# UPD70F3508 register map
Vendor: Renesas; Series: V850E2/Px4; File version: 1.0
CPU: other r0p0, little endian, no MPU, FPU, 4 interrupt priority bits
Registers are 8-bit, read-write, reset 0x0 unless marked. A register's access mark holds for its fields unless they carry their own. Offsets are from the block's base; [hi:lo] are bit positions.

## TAPA0 — Timer Option Module 0 Status and Trigger Registers (base1 region)
Base 0xFFFFD400
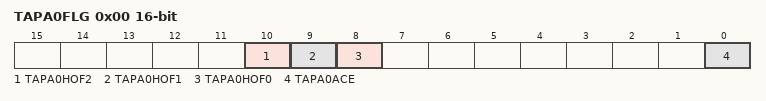
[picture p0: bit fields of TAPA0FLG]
0x00 TAPA0FLG 16-bit ro — TAPA0 Flag Register - Hi-Z output monitor and async control state
  [10] TAPA0HOF2 — HZOUTm output monitor bit 2 (phase W)
  [9] TAPA0HOF1 — HZOUTm output monitor bit 1 (phase V)
  [8] TAPA0HOF0 — HZOUTm output monitor bit 0 (phase U)
  [0] TAPA0ACE — Asynchronous Hi-Z control enable bit
0x04 TAPA0ACWE — TAPA0 Asynchronous Control Write Enable Register
  [0] TAPA0ACWE — Async control write enable bit (auto-cleared after ACTS/ACTT write)
0x08 TAPA0ACTS wo — TAPA0 Asynchronous Control Start Trigger Register
  [0] TAPA0ACTS — Async control start trigger bit (valid when ACWE=1)
0x0C TAPA0ACTT wo — TAPA0 Asynchronous Control Stop Trigger Register
  [0] TAPA0ACTT — Async control stop trigger bit (valid when ACWE=1)
0x14 TAPA0OPHS wo — TAPA0 Hi-Z Start Trigger Register
  [0] TAPA0OPHS0 — Hi-Z control signal start trigger 0 bit
0x18 TAPA0OPHT wo — TAPA0 Hi-Z Stop Trigger Register
  [0] TAPA0OPHT0 — Hi-Z control signal stop trigger 0 bit

## TAPA1 — Timer Option Module 1 Status and Trigger Registers (base1 region)
Base 0xFFFFD500
Registers as TAPA0 (with TAPA0 read as TAPA1).

## TAPA2 — Timer Option Module 2 Status and Trigger Registers (base1 region)
Base 0xFFFFD600
Registers as TAPA0 (with TAPA0 read as TAPA2); these are added or differ:
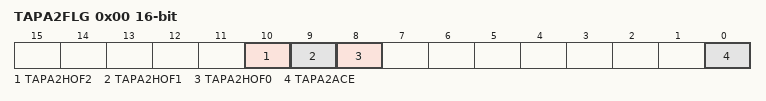
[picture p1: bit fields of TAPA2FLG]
0x00 TAPA2FLG 16-bit ro — TAPA2 Flag Register - Hi-Z output monitor and async control state
  [10] TAPA2HOF2 — HZOUTm output monitor bit 2
  [9] TAPA2HOF1 — HZOUTm output monitor bit 1
  [8] TAPA2HOF0 — HZOUTm output monitor bit 0
  [0] TAPA2ACE — Asynchronous Hi-Z control enable bit
0x04 TAPA2ACWE — TAPA2 Asynchronous Control Write Enable Register
  [0] TAPA2ACWE — Async control write enable bit

## TAPA3 — Timer Option Module 3 Status and Trigger Registers (base1 region)
Base 0xFFFFD700
Registers as TAPA2 (with TAPA2 read as TAPA3).

## ENCA0 — Encoder Timer 0 — main register bank (base1 = 0xFFFFD800)
Base 0xFFFFD800
0x00 ENCA0CCR0 16-bit — ENCA0 Capture/Compare Register 0
  [15:0] CCR0 — Capture/compare value [15:0]
0x04 ENCA0CCR1 16-bit — ENCA0 Capture/Compare Register 1
  [15:0] CCR1 — Capture/compare value [15:0]
0x08 ENCA0CNT 16-bit — ENCA0 Counter Register
  [15:0] CNT — 16-bit up/down counter value
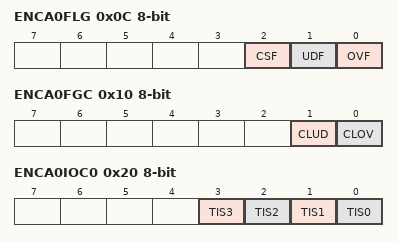
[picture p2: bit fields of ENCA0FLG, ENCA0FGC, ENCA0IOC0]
0x0C ENCA0FLG ro — ENCA0 Status Flag Register
  [2] CSF — Count direction flag: 0=counting up, 1=counting down
  [1] UDF — Underflow flag: set when counter wraps FFFF->0000 (down)
  [0] OVF — Overflow flag: set when counter wraps FFFF->0000 (up)
0x10 ENCA0FGC wo — ENCA0 Status Flag Clear Register (always reads 00H)
  [1] CLUD — Write 1 to clear UDF underflow flag
  [0] CLOV — Write 1 to clear OVF overflow flag
0x14 ENCA0TE ro — ENCA0 Timer Enable Status Register
  [0] TE — Timer operation status: 0=stopped, 1=enabled
0x18 ENCA0TS wo — ENCA0 Timer Start Trigger Register (always reads 00H)
  [0] TS — Write 1 to start timer (sets TE bit to 1)
0x1C ENCA0TT wo — ENCA0 Timer Stop Trigger Register (always reads 00H)
  [0] TT — Write 1 to stop timer (clears TE bit to 0)
0x20 ENCA0IOC0 — ENCA0 I/O Control Register 0 — capture trigger edge selection
  [3] TIS3 — Capture trigger 1 (ENCAnI1) valid edge bit 1
  [2] TIS2 — Capture trigger 1 (ENCAnI1) valid edge bit 0
  [1] TIS1 — Capture trigger 0 (ENCAnI0) valid edge bit 1
  [0] TIS0 — Capture trigger 0 (ENCAnI0) valid edge bit 0

## ENCA1 — Encoder Timer 1 — main register bank (base1 = 0xFFFFD900)
Base 0xFFFFD900
Registers as ENCA0 (with ENCA0 read as ENCA1).
